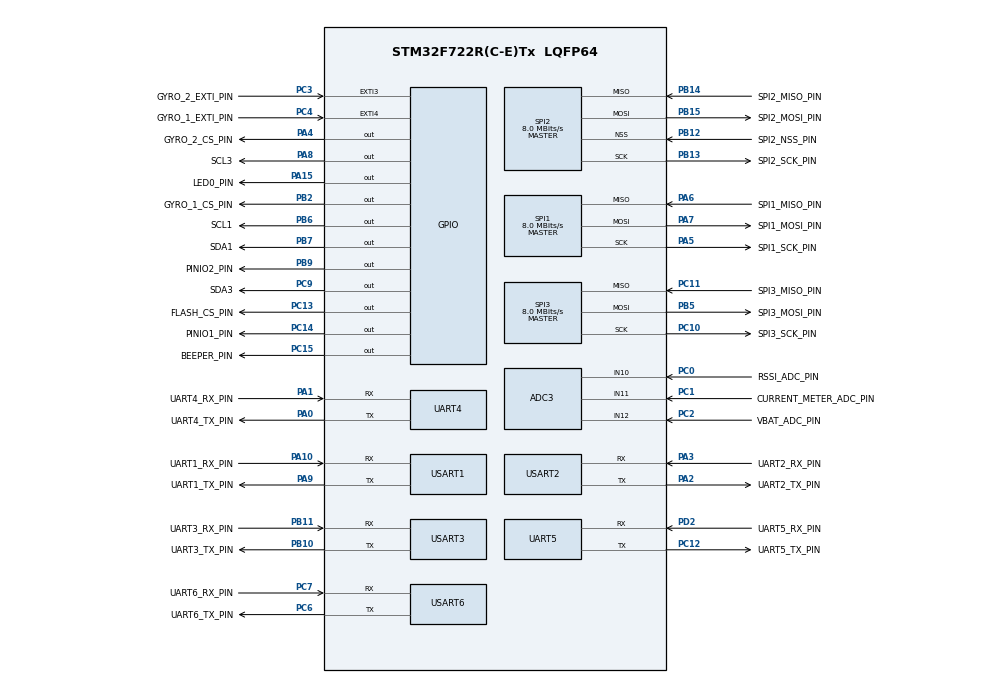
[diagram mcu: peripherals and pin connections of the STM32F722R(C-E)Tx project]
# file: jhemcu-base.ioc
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ADC3.Channel-1\#ChannelRegularConversion=ADC_CHANNEL_10
ADC3.NbrOfConversionFlag=1
ADC3.Rank-1\#ChannelRegularConversion=1
ADC3.SamplingTime-1\#ChannelRegularConversion=ADC_SAMPLETIME_3CYCLES
Dma.ADC3.0.Direction=DMA_PERIPH_TO_MEMORY
Dma.ADC3.0.FIFOMode=DMA_FIFOMODE_DISABLE
Dma.ADC3.0.Instance=DMA2_Stream0
Dma.ADC3.0.MemDataAlignment=DMA_MDATAALIGN_HALFWORD
Dma.ADC3.0.MemInc=DMA_MINC_ENABLE
Dma.ADC3.0.Mode=DMA_NORMAL
Dma.ADC3.0.PeriphDataAlignment=DMA_PDATAALIGN_HALFWORD
Dma.ADC3.0.PeriphInc=DMA_PINC_DISABLE
Dma.ADC3.0.Priority=DMA_PRIORITY_LOW
Dma.Request0=ADC3
Mcu.Family=STM32F7
Mcu.Name=STM32F722R(C-E)Tx
Mcu.Package=LQFP64
Mcu.UserConstants=TARGET,"JHEF7DUAL";ID,"JH7D";GYRO_1_SPI_INSTANCE,1;GYRO_2_SPI_INSTANCE,1;BARO_I2C_INSTANCE,1;MAX7456_SPI_INSTANCE,2;MAX7456_SPI_CS_PIN,"SPI2_NSS_PIN";FLASH_SPI_INSTANCE,3;CURRENT_METER_SCALE_DEFAULT,450
NVIC.DMA2_Stream0_IRQn=true\:0\:0\:false\:false\:true\:false\:true
NVIC.EXTI3_IRQn=true\:0\:0\:false\:false\:true\:true\:true
NVIC.EXTI4_IRQn=true\:0\:0\:false\:false\:true\:true\:true
NVIC.PriorityGroup=NVIC_PRIORITYGROUP_4
PA0-WKUP.GPIO_Label=UART4_TX_PIN
PA0-WKUP.Mode=Asynchronous
PA0-WKUP.Signal=UART4_TX
PA1.GPIO_Label=UART4_RX_PIN
PA1.Mode=Asynchronous
PA1.Signal=UART4_RX
PA10.GPIO_Label=UART1_RX_PIN
PA10.Mode=Asynchronous
PA10.Signal=USART1_RX
PA13.Mode=Serial_Wire
PA13.Signal=SYS_JTMS-SWDIO
PA14.Mode=Serial_Wire
PA14.Signal=SYS_JTCK-SWCLK
PA15.GPIO_Label=LED0_PIN
PA15.Signal=GPIO_Output
PA2.GPIO_Label=UART2_TX_PIN
PA2.Mode=Asynchronous
PA2.Signal=USART2_TX
PA3.GPIO_Label=UART2_RX_PIN
PA3.Mode=Asynchronous
PA3.Signal=USART2_RX
PA4.GPIO_Label=GYRO_2_CS_PIN
PA4.Signal=GPIO_Output
PA5.GPIO_Label=SPI1_SCK_PIN
PA5.Mode=Full_Duplex_Master
PA5.Signal=SPI1_SCK
PA6.GPIO_Label=SPI1_MISO_PIN
PA6.Mode=Full_Duplex_Master
PA6.Signal=SPI1_MISO
PA7.GPIO_Label=SPI1_MOSI_PIN
PA7.Mode=Full_Duplex_Master
PA7.Signal=SPI1_MOSI
PA8.GPIO_Label=SCL3
PA8.Signal=GPIO_Output
PA9.GPIO_Label=UART1_TX_PIN
PA9.Mode=Asynchronous
PA9.Signal=USART1_TX
PB10.GPIO_Label=UART3_TX_PIN
PB10.Mode=Asynchronous
PB10.Signal=USART3_TX
PB11.GPIO_Label=UART3_RX_PIN
PB11.Mode=Asynchronous
PB11.Signal=USART3_RX
PB12.GPIO_Label=SPI2_NSS_PIN
PB12.Mode=NSS_Signal_Hard_Input
PB12.Signal=SPI2_NSS
PB13.GPIO_Label=SPI2_SCK_PIN
PB13.Mode=Full_Duplex_Master
PB13.Signal=SPI2_SCK
PB14.GPIO_Label=SPI2_MISO_PIN
PB14.Mode=Full_Duplex_Master
PB14.Signal=SPI2_MISO
PB15.GPIO_Label=SPI2_MOSI_PIN
PB15.Mode=Full_Duplex_Master
PB15.Signal=SPI2_MOSI
PB2.GPIO_Label=GYRO_1_CS_PIN
PB2.Signal=GPIO_Output
PB5.GPIO_Label=SPI3_MOSI_PIN
PB5.Mode=Full_Duplex_Master
PB5.Signal=SPI3_MOSI
PB6.GPIO_Label=SCL1
PB6.Signal=GPIO_Output
PB7.GPIO_Label=SDA1
PB7.Signal=GPIO_Output
PB9.GPIO_Label=PINIO2_PIN
PB9.Signal=GPIO_Output
PC0.GPIO_Label=RSSI_ADC_PIN
PC0.Signal=ADCx_IN10
PC1.GPIO_Label=CURRENT_METER_ADC_PIN
PC1.Signal=ADCx_IN11
PC10.GPIO_Label=SPI3_SCK_PIN
PC10.Mode=Full_Duplex_Master
PC10.Signal=SPI3_SCK
PC11.GPIO_Label=SPI3_MISO_PIN
PC11.Mode=Full_Duplex_Master
PC11.Signal=SPI3_MISO
PC12.GPIO_Label=UART5_TX_PIN
PC12.Mode=Asynchronous
PC12.Signal=UART5_TX
PC13.GPIO_Label=FLASH_CS_PIN
PC13.Signal=GPIO_Output
PC14-OSC32_IN.GPIO_Label=PINIO1_PIN
PC14-OSC32_IN.Signal=GPIO_Output
PC15-OSC32_OUT.GPIO_Label=BEEPER_PIN
PC15-OSC32_OUT.Signal=GPIO_Output
PC2.GPIO_Label=VBAT_ADC_PIN
PC2.Signal=ADCx_IN12
PC3.GPIO_Label=GYRO_2_EXTI_PIN
PC3.Signal=GPXTI3
PC4.GPIO_Label=GYRO_1_EXTI_PIN
PC4.Signal=GPXTI4
PC6.GPIO_Label=UART6_TX_PIN
PC6.Mode=Asynchronous
PC6.Signal=USART6_TX
PC7.GPIO_Label=UART6_RX_PIN
PC7.Mode=Asynchronous
PC7.Signal=USART6_RX
PC9.GPIO_Label=SDA3
PC9.Signal=GPIO_Output
PD2.GPIO_Label=UART5_RX_PIN
PD2.Mode=Asynchronous
PD2.Signal=UART5_RX
PH0-OSC_IN.Mode=HSE-External-Oscillator
PH0-OSC_IN.Signal=RCC_OSC_IN
PH1-OSC_OUT.Mode=HSE-External-Oscillator
PH1-OSC_OUT.Signal=RCC_OSC_OUT
ProjectManager.HeapSize=0x200
ProjectManager.StackSize=0x400
ProjectManager.TargetToolchain=STM32CubeIDE
RCC.HSE_VALUE=25000000
RCC.HSI_VALUE=16000000
RCC.LSE_VALUE=32768
RCC.USBFreq_Value=96000000
RCC.VCOOutputFreq_Value=192000000
SH.ADCx_IN10.0=ADC3_IN10,IN10
SH.ADCx_IN11.0=ADC3_IN11,IN11
SH.ADCx_IN12.0=ADC3_IN12,IN12
SPI1.CalculateBaudRate=8.0 MBits/s
SPI1.Direction=SPI_DIRECTION_2LINES
SPI1.Mode=SPI_MODE_MASTER
SPI1.VirtualType=VM_MASTER
SPI2.CalculateBaudRate=8.0 MBits/s
SPI2.Direction=SPI_DIRECTION_2LINES
SPI2.Mode=SPI_MODE_MASTER
SPI2.VirtualNSS=VM_NSSHARD
SPI2.VirtualType=VM_MASTER
SPI3.CalculateBaudRate=8.0 MBits/s
SPI3.Direction=SPI_DIRECTION_2LINES
SPI3.Mode=SPI_MODE_MASTER
SPI3.VirtualType=VM_MASTER
USART1.VirtualMode-Asynchronous=VM_ASYNC
USART2.VirtualMode-Asynchronous=VM_ASYNC
USART3.VirtualMode-Asynchronous=VM_ASYNC
USART6.VirtualMode=VM_ASYNC
board=custom

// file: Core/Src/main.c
/* USER CODE BEGIN Header */
/**
  ******************************************************************************
  * @file           : main.c
  * @brief          : Main program body
  ******************************************************************************
  * @attention
  *
  * <h2><center>&copy; Copyright (c) 2019 STMicroelectronics.
  * All rights reserved.</center></h2>
  *
  * This software component is licensed by ST under BSD 3-Clause license,
  * the "License"; You may not use this file except in compliance with the
  * License. You may obtain a copy of the License at:
  *                        opensource.org/licenses/BSD-3-Clause
  *
  ******************************************************************************
  */
/* USER CODE END Header */

#include "main.h"

ADC_HandleTypeDef hadc3;
DMA_HandleTypeDef hdma_adc3;

SPI_HandleTypeDef hspi1;
SPI_HandleTypeDef hspi2;
SPI_HandleTypeDef hspi3;

UART_HandleTypeDef huart4;
UART_HandleTypeDef huart5;
UART_HandleTypeDef huart1;
UART_HandleTypeDef huart2;
UART_HandleTypeDef huart3;
UART_HandleTypeDef huart6;

void SystemClock_Config(void);
static void MX_GPIO_Init(void);
static void MX_DMA_Init(void);
static void MX_ADC3_Init(void);
static void MX_SPI1_Init(void);
static void MX_SPI2_Init(void);
static void MX_SPI3_Init(void);
static void MX_UART4_Init(void);
static void MX_UART5_Init(void);
static void MX_USART1_UART_Init(void);
static void MX_USART2_UART_Init(void);
static void MX_USART3_UART_Init(void);
static void MX_USART6_UART_Init(void);

int main(void)
{

  /* MCU Configuration--------------------------------------------------------*/

  /* Reset of all peripherals, Initializes the Flash interface and the Systick. */
  HAL_Init();

  /* Configure the system clock */
  SystemClock_Config();

  /* Initialize all configured peripherals */
  MX_GPIO_Init();
  MX_DMA_Init();
  MX_ADC3_Init();
  MX_SPI1_Init();
  MX_SPI2_Init();
  MX_SPI3_Init();
  MX_UART4_Init();
  MX_UART5_Init();
  MX_USART1_UART_Init();
  MX_USART2_UART_Init();
  MX_USART3_UART_Init();
  MX_USART6_UART_Init();

  /* Infinite loop */
  /* USER CODE BEGIN WHILE */
  GPIO_PinState pin_state = GPIO_PIN_RESET;

  while (1)
  {
    HAL_GPIO_TogglePin(LED0_PIN_GPIO_Port, LED0_PIN_Pin);

    pin_state = (pin_state == GPIO_PIN_RESET) ? GPIO_PIN_SET : GPIO_PIN_RESET;
    HAL_GPIO_WritePin(SDA1_GPIO_Port, SDA1_Pin, pin_state);
    HAL_GPIO_WritePin(SCL1_GPIO_Port, SCL1_Pin, pin_state);
    HAL_GPIO_WritePin(SDA3_GPIO_Port, SDA3_Pin, pin_state);
    HAL_GPIO_WritePin(SCL3_GPIO_Port, SCL3_Pin, pin_state);

    HAL_Delay(100);

    // Check pin status
    uint8_t match = (HAL_GPIO_ReadPin(SDA1_GPIO_Port, SDA1_Pin) == pin_state
        && HAL_GPIO_ReadPin(SCL1_GPIO_Port, SCL1_Pin) == pin_state
        && HAL_GPIO_ReadPin(SDA3_GPIO_Port, SDA3_Pin) == pin_state
        && HAL_GPIO_ReadPin(SCL3_GPIO_Port, SCL3_Pin) == pin_state);

    // Blink faster if status not as expected
    if (match) {
      HAL_Delay(900);
    }

    /* USER CODE END WHILE */

  }
}

void SystemClock_Config(void)
{
  RCC_OscInitTypeDef RCC_OscInitStruct = {0};
  RCC_ClkInitTypeDef RCC_ClkInitStruct = {0};
  RCC_PeriphCLKInitTypeDef PeriphClkInitStruct = {0};

  /** Configure the main internal regulator output voltage
  */
  __HAL_RCC_PWR_CLK_ENABLE();
  __HAL_PWR_VOLTAGESCALING_CONFIG(PWR_REGULATOR_VOLTAGE_SCALE3);
  /** Initializes the CPU, AHB and APB busses clocks
  */
  RCC_OscInitStruct.OscillatorType = RCC_OSCILLATORTYPE_HSI;
  RCC_OscInitStruct.HSIState = RCC_HSI_ON;
  RCC_OscInitStruct.HSICalibrationValue = RCC_HSICALIBRATION_DEFAULT;
  RCC_OscInitStruct.PLL.PLLState = RCC_PLL_NONE;
  if (HAL_RCC_OscConfig(&RCC_OscInitStruct) != HAL_OK)
  {
    Error_Handler();
  }
  /** Initializes the CPU, AHB and APB busses clocks
  */
  RCC_ClkInitStruct.ClockType = RCC_CLOCKTYPE_HCLK|RCC_CLOCKTYPE_SYSCLK
                              |RCC_CLOCKTYPE_PCLK1|RCC_CLOCKTYPE_PCLK2;
  RCC_ClkInitStruct.SYSCLKSource = RCC_SYSCLKSOURCE_HSI;
  RCC_ClkInitStruct.AHBCLKDivider = RCC_SYSCLK_DIV1;
  RCC_ClkInitStruct.APB1CLKDivider = RCC_HCLK_DIV1;
  RCC_ClkInitStruct.APB2CLKDivider = RCC_HCLK_DIV1;

  if (HAL_RCC_ClockConfig(&RCC_ClkInitStruct, FLASH_LATENCY_0) != HAL_OK)
  {
    Error_Handler();
  }
  PeriphClkInitStruct.PeriphClockSelection = RCC_PERIPHCLK_USART1|RCC_PERIPHCLK_USART2
                              |RCC_PERIPHCLK_USART3|RCC_PERIPHCLK_USART6
                              |RCC_PERIPHCLK_UART4|RCC_PERIPHCLK_UART5;
  PeriphClkInitStruct.Usart1ClockSelection = RCC_USART1CLKSOURCE_PCLK2;
  PeriphClkInitStruct.Usart2ClockSelection = RCC_USART2CLKSOURCE_PCLK1;
  PeriphClkInitStruct.Usart3ClockSelection = RCC_USART3CLKSOURCE_PCLK1;
  PeriphClkInitStruct.Uart4ClockSelection = RCC_UART4CLKSOURCE_PCLK1;
  PeriphClkInitStruct.Uart5ClockSelection = RCC_UART5CLKSOURCE_PCLK1;
  PeriphClkInitStruct.Usart6ClockSelection = RCC_USART6CLKSOURCE_PCLK2;
  if (HAL_RCCEx_PeriphCLKConfig(&PeriphClkInitStruct) != HAL_OK)
  {
    Error_Handler();
  }
}

static void MX_ADC3_Init(void)
{

  ADC_ChannelConfTypeDef sConfig = {0};

  /** Configure the global features of the ADC (Clock, Resolution, Data Alignment and number of conversion)
  */
  hadc3.Instance = ADC3;
  hadc3.Init.ClockPrescaler = ADC_CLOCK_SYNC_PCLK_DIV2;
  hadc3.Init.Resolution = ADC_RESOLUTION_12B;
  hadc3.Init.ScanConvMode = ADC_SCAN_DISABLE;
  hadc3.Init.ContinuousConvMode = DISABLE;
  hadc3.Init.DiscontinuousConvMode = DISABLE;
  hadc3.Init.ExternalTrigConvEdge = ADC_EXTERNALTRIGCONVEDGE_NONE;
  hadc3.Init.ExternalTrigConv = ADC_SOFTWARE_START;
  hadc3.Init.DataAlign = ADC_DATAALIGN_RIGHT;
  hadc3.Init.NbrOfConversion = 1;
  hadc3.Init.DMAContinuousRequests = DISABLE;
  hadc3.Init.EOCSelection = ADC_EOC_SINGLE_CONV;
  if (HAL_ADC_Init(&hadc3) != HAL_OK)
  {
    Error_Handler();
  }
  /** Configure for the selected ADC regular channel its corresponding rank in the sequencer and its sample time.
  */
  sConfig.Channel = ADC_CHANNEL_10;
  sConfig.Rank = ADC_REGULAR_RANK_1;
  sConfig.SamplingTime = ADC_SAMPLETIME_3CYCLES;
  if (HAL_ADC_ConfigChannel(&hadc3, &sConfig) != HAL_OK)
  {
    Error_Handler();
  }

}

static void MX_SPI1_Init(void)
{

  /* SPI1 parameter configuration*/
  hspi1.Instance = SPI1;
  hspi1.Init.Mode = SPI_MODE_MASTER;
  hspi1.Init.Direction = SPI_DIRECTION_2LINES;
  hspi1.Init.DataSize = SPI_DATASIZE_4BIT;
  hspi1.Init.CLKPolarity = SPI_POLARITY_LOW;
  hspi1.Init.CLKPhase = SPI_PHASE_1EDGE;
  hspi1.Init.NSS = SPI_NSS_SOFT;
  hspi1.Init.BaudRatePrescaler = SPI_BAUDRATEPRESCALER_2;
  hspi1.Init.FirstBit = SPI_FIRSTBIT_MSB;
  hspi1.Init.TIMode = SPI_TIMODE_DISABLE;
  hspi1.Init.CRCCalculation = SPI_CRCCALCULATION_DISABLE;
  hspi1.Init.CRCPolynomial = 7;
  hspi1.Init.CRCLength = SPI_CRC_LENGTH_DATASIZE;
  hspi1.Init.NSSPMode = SPI_NSS_PULSE_ENABLE;
  if (HAL_SPI_Init(&hspi1) != HAL_OK)
  {
    Error_Handler();
  }

}

static void MX_SPI2_Init(void)
{

  /* SPI2 parameter configuration*/
  hspi2.Instance = SPI2;
  hspi2.Init.Mode = SPI_MODE_MASTER;
  hspi2.Init.Direction = SPI_DIRECTION_2LINES;
  hspi2.Init.DataSize = SPI_DATASIZE_4BIT;
  hspi2.Init.CLKPolarity = SPI_POLARITY_LOW;
  hspi2.Init.CLKPhase = SPI_PHASE_1EDGE;
  hspi2.Init.NSS = SPI_NSS_HARD_INPUT;
  hspi2.Init.BaudRatePrescaler = SPI_BAUDRATEPRESCALER_2;
  hspi2.Init.FirstBit = SPI_FIRSTBIT_MSB;
  hspi2.Init.TIMode = SPI_TIMODE_DISABLE;
  hspi2.Init.CRCCalculation = SPI_CRCCALCULATION_DISABLE;
  hspi2.Init.CRCPolynomial = 7;
  hspi2.Init.CRCLength = SPI_CRC_LENGTH_DATASIZE;
  hspi2.Init.NSSPMode = SPI_NSS_PULSE_ENABLE;
  if (HAL_SPI_Init(&hspi2) != HAL_OK)
  {
    Error_Handler();
  }

}

static void MX_SPI3_Init(void)
{

  /* SPI3 parameter configuration*/
  hspi3.Instance = SPI3;
  hspi3.Init.Mode = SPI_MODE_MASTER;
  hspi3.Init.Direction = SPI_DIRECTION_2LINES;
  hspi3.Init.DataSize = SPI_DATASIZE_4BIT;
  hspi3.Init.CLKPolarity = SPI_POLARITY_LOW;
  hspi3.Init.CLKPhase = SPI_PHASE_1EDGE;
  hspi3.Init.NSS = SPI_NSS_SOFT;
  hspi3.Init.BaudRatePrescaler = SPI_BAUDRATEPRESCALER_2;
  hspi3.Init.FirstBit = SPI_FIRSTBIT_MSB;
  hspi3.Init.TIMode = SPI_TIMODE_DISABLE;
  hspi3.Init.CRCCalculation = SPI_CRCCALCULATION_DISABLE;
  hspi3.Init.CRCPolynomial = 7;
  hspi3.Init.CRCLength = SPI_CRC_LENGTH_DATASIZE;
  hspi3.Init.NSSPMode = SPI_NSS_PULSE_ENABLE;
  if (HAL_SPI_Init(&hspi3) != HAL_OK)
  {
    Error_Handler();
  }

}

static void MX_UART4_Init(void)
{

  huart4.Instance = UART4;
  huart4.Init.BaudRate = 115200;
  huart4.Init.WordLength = UART_WORDLENGTH_8B;
  huart4.Init.StopBits = UART_STOPBITS_1;
  huart4.Init.Parity = UART_PARITY_NONE;
  huart4.Init.Mode = UART_MODE_TX_RX;
  huart4.Init.HwFlowCtl = UART_HWCONTROL_NONE;
  huart4.Init.OverSampling = UART_OVERSAMPLING_16;
  huart4.Init.OneBitSampling = UART_ONE_BIT_SAMPLE_DISABLE;
  huart4.AdvancedInit.AdvFeatureInit = UART_ADVFEATURE_NO_INIT;
  if (HAL_UART_Init(&huart4) != HAL_OK)
  {
    Error_Handler();
  }

}

static void MX_UART5_Init(void)
{

  huart5.Instance = UART5;
  huart5.Init.BaudRate = 115200;
  huart5.Init.WordLength = UART_WORDLENGTH_8B;
  huart5.Init.StopBits = UART_STOPBITS_1;
  huart5.Init.Parity = UART_PARITY_NONE;
  huart5.Init.Mode = UART_MODE_TX_RX;
  huart5.Init.HwFlowCtl = UART_HWCONTROL_NONE;
  huart5.Init.OverSampling = UART_OVERSAMPLING_16;
  huart5.Init.OneBitSampling = UART_ONE_BIT_SAMPLE_DISABLE;
  huart5.AdvancedInit.AdvFeatureInit = UART_ADVFEATURE_NO_INIT;
  if (HAL_UART_Init(&huart5) != HAL_OK)
  {
    Error_Handler();
  }

}

static void MX_USART1_UART_Init(void)
{

  huart1.Instance = USART1;
  huart1.Init.BaudRate = 115200;
  huart1.Init.WordLength = UART_WORDLENGTH_8B;
  huart1.Init.StopBits = UART_STOPBITS_1;
  huart1.Init.Parity = UART_PARITY_NONE;
  huart1.Init.Mode = UART_MODE_TX_RX;
  huart1.Init.HwFlowCtl = UART_HWCONTROL_NONE;
  huart1.Init.OverSampling = UART_OVERSAMPLING_16;
  huart1.Init.OneBitSampling = UART_ONE_BIT_SAMPLE_DISABLE;
  huart1.AdvancedInit.AdvFeatureInit = UART_ADVFEATURE_NO_INIT;
  if (HAL_UART_Init(&huart1) != HAL_OK)
  {
    Error_Handler();
  }

}

static void MX_USART2_UART_Init(void)
{

  huart2.Instance = USART2;
  huart2.Init.BaudRate = 115200;
  huart2.Init.WordLength = UART_WORDLENGTH_8B;
  huart2.Init.StopBits = UART_STOPBITS_1;
  huart2.Init.Parity = UART_PARITY_NONE;
  huart2.Init.Mode = UART_MODE_TX_RX;
  huart2.Init.HwFlowCtl = UART_HWCONTROL_NONE;
  huart2.Init.OverSampling = UART_OVERSAMPLING_16;
  huart2.Init.OneBitSampling = UART_ONE_BIT_SAMPLE_DISABLE;
  huart2.AdvancedInit.AdvFeatureInit = UART_ADVFEATURE_NO_INIT;
  if (HAL_UART_Init(&huart2) != HAL_OK)
  {
    Error_Handler();
  }

}

static void MX_USART3_UART_Init(void)
{

  huart3.Instance = USART3;
  huart3.Init.BaudRate = 115200;
  huart3.Init.WordLength = UART_WORDLENGTH_8B;
  huart3.Init.StopBits = UART_STOPBITS_1;
  huart3.Init.Parity = UART_PARITY_NONE;
  huart3.Init.Mode = UART_MODE_TX_RX;
  huart3.Init.HwFlowCtl = UART_HWCONTROL_NONE;
  huart3.Init.OverSampling = UART_OVERSAMPLING_16;
  huart3.Init.OneBitSampling = UART_ONE_BIT_SAMPLE_DISABLE;
  huart3.AdvancedInit.AdvFeatureInit = UART_ADVFEATURE_NO_INIT;
  if (HAL_UART_Init(&huart3) != HAL_OK)
  {
    Error_Handler();
  }

}

static void MX_USART6_UART_Init(void)
{

  huart6.Instance = USART6;
  huart6.Init.BaudRate = 115200;
  huart6.Init.WordLength = UART_WORDLENGTH_8B;
  huart6.Init.StopBits = UART_STOPBITS_1;
  huart6.Init.Parity = UART_PARITY_NONE;
  huart6.Init.Mode = UART_MODE_TX_RX;
  huart6.Init.HwFlowCtl = UART_HWCONTROL_NONE;
  huart6.Init.OverSampling = UART_OVERSAMPLING_16;
  huart6.Init.OneBitSampling = UART_ONE_BIT_SAMPLE_DISABLE;
  huart6.AdvancedInit.AdvFeatureInit = UART_ADVFEATURE_NO_INIT;
  if (HAL_UART_Init(&huart6) != HAL_OK)
  {
    Error_Handler();
  }

}

static void MX_DMA_Init(void)
{

  /* DMA controller clock enable */
  __HAL_RCC_DMA2_CLK_ENABLE();

  /* DMA interrupt init */
  /* DMA2_Stream0_IRQn interrupt configuration */
  HAL_NVIC_SetPriority(DMA2_Stream0_IRQn, 0, 0);
  HAL_NVIC_EnableIRQ(DMA2_Stream0_IRQn);

}

static void MX_GPIO_Init(void)
{
  GPIO_InitTypeDef GPIO_InitStruct = {0};

  /* GPIO Ports Clock Enable */
  __HAL_RCC_GPIOC_CLK_ENABLE();
  __HAL_RCC_GPIOH_CLK_ENABLE();
  __HAL_RCC_GPIOA_CLK_ENABLE();
  __HAL_RCC_GPIOB_CLK_ENABLE();
  __HAL_RCC_GPIOD_CLK_ENABLE();

  /*Configure GPIO pin Output Level */
  HAL_GPIO_WritePin(GPIOC, FLASH_CS_PIN_Pin|PINIO1_PIN_Pin|BEEPER_PIN_Pin|SDA3_Pin, GPIO_PIN_RESET);

  /*Configure GPIO pin Output Level */
  HAL_GPIO_WritePin(GPIOA, GYRO_2_CS_PIN_Pin|SCL3_Pin|LED0_PIN_Pin, GPIO_PIN_RESET);

  /*Configure GPIO pin Output Level */
  HAL_GPIO_WritePin(GPIOB, GYRO_1_CS_PIN_Pin|SCL1_Pin|SDA1_Pin|PINIO2_PIN_Pin, GPIO_PIN_RESET);

  /*Configure GPIO pins : FLASH_CS_PIN_Pin PINIO1_PIN_Pin BEEPER_PIN_Pin SDA3_Pin */
  GPIO_InitStruct.Pin = FLASH_CS_PIN_Pin|PINIO1_PIN_Pin|BEEPER_PIN_Pin|SDA3_Pin;
  GPIO_InitStruct.Mode = GPIO_MODE_OUTPUT_PP;
  GPIO_InitStruct.Pull = GPIO_NOPULL;
  GPIO_InitStruct.Speed = GPIO_SPEED_FREQ_LOW;
  HAL_GPIO_Init(GPIOC, &GPIO_InitStruct);

  /*Configure GPIO pins : GYRO_2_EXTI_PIN_Pin GYRO_1_EXTI_PIN_Pin */
  GPIO_InitStruct.Pin = GYRO_2_EXTI_PIN_Pin|GYRO_1_EXTI_PIN_Pin;
  GPIO_InitStruct.Mode = GPIO_MODE_IT_RISING;
  GPIO_InitStruct.Pull = GPIO_NOPULL;
  HAL_GPIO_Init(GPIOC, &GPIO_InitStruct);

  /*Configure GPIO pins : GYRO_2_CS_PIN_Pin SCL3_Pin LED0_PIN_Pin */
  GPIO_InitStruct.Pin = GYRO_2_CS_PIN_Pin|SCL3_Pin|LED0_PIN_Pin;
  GPIO_InitStruct.Mode = GPIO_MODE_OUTPUT_PP;
  GPIO_InitStruct.Pull = GPIO_NOPULL;
  GPIO_InitStruct.Speed = GPIO_SPEED_FREQ_LOW;
  HAL_GPIO_Init(GPIOA, &GPIO_InitStruct);

  /*Configure GPIO pins : GYRO_1_CS_PIN_Pin SCL1_Pin SDA1_Pin PINIO2_PIN_Pin */
  GPIO_InitStruct.Pin = GYRO_1_CS_PIN_Pin|SCL1_Pin|SDA1_Pin|PINIO2_PIN_Pin;
  GPIO_InitStruct.Mode = GPIO_MODE_OUTPUT_PP;
  GPIO_InitStruct.Pull = GPIO_NOPULL;
  GPIO_InitStruct.Speed = GPIO_SPEED_FREQ_LOW;
  HAL_GPIO_Init(GPIOB, &GPIO_InitStruct);

  /* EXTI interrupt init*/
  HAL_NVIC_SetPriority(EXTI3_IRQn, 0, 0);
  HAL_NVIC_EnableIRQ(EXTI3_IRQn);

  HAL_NVIC_SetPriority(EXTI4_IRQn, 0, 0);
  HAL_NVIC_EnableIRQ(EXTI4_IRQn);

}

void Error_Handler(void)
{
}

/************************ (C) COPYRIGHT STMicroelectronics *****END OF FILE****/
